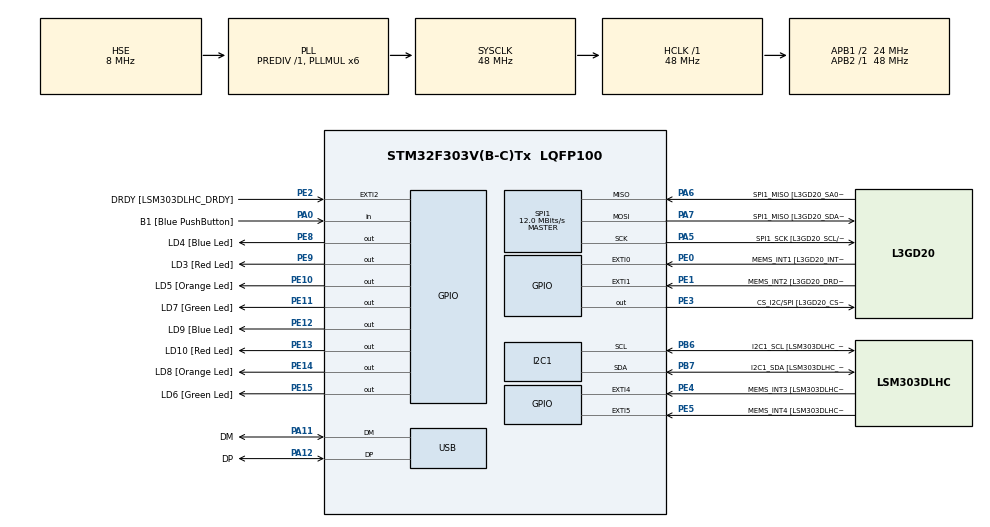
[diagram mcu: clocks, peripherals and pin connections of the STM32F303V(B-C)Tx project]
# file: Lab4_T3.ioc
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I2C1.Timing=0x00201D2B
I2C1.Timing-I2C=0x2000090E
Mcu.Family=STM32F3
Mcu.Name=STM32F303V(B-C)Tx
Mcu.Package=LQFP100
NVIC.PriorityGroup=NVIC_PRIORITYGROUP_0
NVIC.TIM2_IRQn=true\:0\:0\:false\:false\:true\:true\:true\:true
PA0.GPIO_Label=B1 [Blue PushButton]
PA0.Signal=GPIO_Input
PA11.GPIO_Label=DM
PA11.Mode=Device
PA11.Signal=USB_DM
PA12.GPIO_Label=DP
PA12.Mode=Device
PA12.Signal=USB_DP
PA13.GPIO_Label=SWDIO
PA13.Mode=Serial_Wire
PA13.Signal=SYS_JTMS-SWDIO
PA14.GPIO_Label=SWCLK
PA14.Mode=Serial_Wire
PA14.Signal=SYS_JTCK-SWCLK
PA5.GPIO_Label=SPI1_SCK [L3GD20_SCL/SPC]
PA5.Mode=Full_Duplex_Master
PA5.Signal=SPI1_SCK
PA6.GPIO_Label=SPI1_MISO [L3GD20_SA0/SDO]
PA6.Mode=Full_Duplex_Master
PA6.Signal=SPI1_MISO
PA7.GPIO_Label=SPI1_MISO [L3GD20_SDA/SDI/SDO]
PA7.Mode=Full_Duplex_Master
PA7.Signal=SPI1_MOSI
PB3.GPIO_Label=SWO
PB3.Signal=SYS_JTDO-TRACESWO
PB6.GPIO_Label=I2C1_SCL [LSM303DLHC_SCL]
PB6.GPIO_Pu=GPIO_PULLUP
PB6.Mode=I2C
PB6.Signal=I2C1_SCL
PB7.GPIO_Label=I2C1_SDA [LSM303DLHC_SDA]
PB7.GPIO_Pu=GPIO_PULLUP
PB7.Mode=I2C
PB7.Signal=I2C1_SDA
PC14-OSC32_IN.GPIO_Label=OSC32_IN
PC14-OSC32_IN.Signal=RCC_OSC32_IN
PC15-OSC32_OUT.GPIO_Label=OSC32_OUT
PC15-OSC32_OUT.Signal=RCC_OSC32_OUT
PE0.GPIO_Label=MEMS_INT1 [L3GD20_INT1]
PE0.GPIO_ModeDefaultEXTI=GPIO_MODE_EVT_RISING
PE0.Signal=GPXTI0
PE1.GPIO_Label=MEMS_INT2 [L3GD20_DRDY/INT2]
PE1.GPIO_ModeDefaultEXTI=GPIO_MODE_EVT_RISING
PE1.Signal=GPXTI1
PE10.GPIO_Label=LD5 [Orange Led]
PE10.Signal=GPIO_Output
PE11.GPIO_Label=LD7 [Green Led]
PE11.Signal=GPIO_Output
PE12.GPIO_Label=LD9 [Blue Led]
PE12.Signal=GPIO_Output
PE13.GPIO_Label=LD10 [Red Led]
PE13.Signal=GPIO_Output
PE14.GPIO_Label=LD8 [Orange Led]
PE14.Signal=GPIO_Output
PE15.GPIO_Label=LD6 [Green Led]
PE15.Signal=GPIO_Output
PE2.GPIO_Label=DRDY [LSM303DLHC_DRDY]
PE2.GPIO_ModeDefaultEXTI=GPIO_MODE_EVT_RISING
PE2.Signal=GPXTI2
PE3.GPIO_Label=CS_I2C/SPI [L3GD20_CS_I2C/SPI]
PE3.Signal=GPIO_Output
PE4.GPIO_Label=MEMS_INT3 [LSM303DLHC_INT1]
PE4.GPIO_ModeDefaultEXTI=GPIO_MODE_EVT_RISING
PE4.Signal=GPXTI4
PE5.GPIO_Label=MEMS_INT4 [LSM303DLHC_INT2]
PE5.GPIO_ModeDefaultEXTI=GPIO_MODE_EVT_RISING
PE5.Signal=GPXTI5
PE8.GPIO_Label=LD4 [Blue Led]
PE8.Signal=GPIO_Output
PE9.GPIO_Label=LD3 [Red Led]
PE9.Signal=GPIO_Output
PF0-OSC_IN.GPIO_Label=OSC_IN
PF0-OSC_IN.Mode=HSE-External-Clock-Source
PF0-OSC_IN.Signal=RCC_OSC_IN
PF1-OSC_OUT.GPIO_Label=OSC_OUT
PF1-OSC_OUT.Signal=RCC_OSC_OUT
ProjectManager.HeapSize=0x200
ProjectManager.StackSize=0x400
ProjectManager.TargetToolchain=CMake
RCC.AHBFreq_Value=48000000
RCC.APB1CLKDivider=RCC_HCLK_DIV2
RCC.APB1Freq_Value=24000000
RCC.APB1TimFreq_Value=48000000
RCC.APB2Freq_Value=48000000
RCC.APB2TimFreq_Value=48000000
RCC.CortexFreq_Value=48000000
RCC.HCLKFreq_Value=48000000
RCC.HSE_VALUE=8000000
RCC.HSI_VALUE=8000000
RCC.LSE_VALUE=32768
RCC.PLLMUL=RCC_PLL_MUL6
RCC.SYSCLKFreq_VALUE=48000000
RCC.SYSCLKSourceVirtual=RCC_SYSCLKSOURCE_PLLCLK
RCC.USBFreq_Value=48000000
SPI1.BaudRatePrescaler=SPI_BAUDRATEPRESCALER_4
SPI1.BaudRatePrescaler-Full_Duplex_Master=SPI_BAUDRATEPRESCALER_2
SPI1.CalculateBaudRate=12.0 MBits/s
SPI1.CalculateBaudRate-Full_Duplex_Master=24.0 MBits/s
SPI1.Direction=SPI_DIRECTION_2LINES
SPI1.Mode=SPI_MODE_MASTER
SPI1.Mode-Full_Duplex_Master=SPI_MODE_MASTER
SPI1.VirtualType=VM_MASTER
TIM2.Prescaler=47999
VP_TIM2_VS_ClockSourceINT.Mode=Internal
board=STM32F3DISCOVERY

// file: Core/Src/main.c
/**
  ******************************************************************************
  * @file           : main.c
  * @brief          : Lab 4 Task 3 - Blink 3 LEDs at Different Rates Using Timer Interrupt
  * @description    : This program uses TIM2 to generate a 1ms interrupt and software counters
  *                   to blink 3 LEDs at different frequencies:
  *                   - LED1: 500 ms (1 Hz)
  *                   - LED2: 200 ms (5 Hz)
  *                   - LED3: 100 ms (10 Hz)
  ******************************************************************************
  * Copyright (c) 2026 STMicroelectronics.
  * All rights reserved.
  ******************************************************************************
  */

#include "main.h"
#include <stdint.h>

/* Structure to hold LED configuration */
typedef struct {
  GPIO_TypeDef* port;
  uint16_t pin;
  uint16_t threshold_ms;
  uint16_t counter;
  uint8_t state;
} LED_Config_t;

#define LED1_THRESHOLD    500   /* 500 ms for 1 Hz blink */
#define LED2_THRESHOLD    200   /* 200 ms for 5 Hz blink */
#define LED3_THRESHOLD    100   /* 100 ms for 10 Hz blink */

I2C_HandleTypeDef hi2c1;
SPI_HandleTypeDef hspi1;
TIM_HandleTypeDef htim2;
PCD_HandleTypeDef hpcd_USB_FS;

/* LED configuration array */
LED_Config_t leds[3];

/* Timer interrupt counter (increments every 1ms) */
static volatile uint32_t timer_ms = 0;

void SystemClock_Config(void);
static void MX_GPIO_Init(void);
static void MX_I2C1_Init(void);
static void MX_SPI1_Init(void);
static void MX_TIM2_Init(void);
static void MX_USB_PCD_Init(void);

/* LED control functions */
static void LED_Init(void);
static void LED_Toggle(LED_Config_t* led);

/**
  * @brief Initialize LED configurations
  * @param None
  * @retval None
  */
static void LED_Init(void)
{
  /* Initialize LED1 (GPIOE, Pin 8) - using onboard LED3 */
  leds[0].port = GPIOE;
  leds[0].pin = GPIO_PIN_8;
  leds[0].threshold_ms = LED1_THRESHOLD;
  leds[0].counter = 0;
  leds[0].state = 0;

  /* Initialize LED2 (GPIOE, Pin 9) - using onboard LED4 */
  leds[1].port = GPIOE;
  leds[1].pin = GPIO_PIN_9;
  leds[1].threshold_ms = LED2_THRESHOLD;
  leds[1].counter = 0;
  leds[1].state = 0;

  /* Initialize LED3 (GPIOE, Pin 10) - using onboard LED5 */
  leds[2].port = GPIOE;
  leds[2].pin = GPIO_PIN_10;
  leds[2].threshold_ms = LED3_THRESHOLD;
  leds[2].counter = 0;
  leds[2].state = 0;

  /* Set all LEDs to OFF initially */
  HAL_GPIO_WritePin(GPIOE, GPIO_PIN_8 | GPIO_PIN_9 | GPIO_PIN_10, GPIO_PIN_RESET);
}

/**
  * @brief Toggle LED and reset counter
  * @param led: Pointer to LED configuration
  * @retval None
  */
static void LED_Toggle(LED_Config_t* led)
{
  if (led->state == 0)
  {
    /* Turn LED ON */
    HAL_GPIO_WritePin(led->port, led->pin, GPIO_PIN_SET);
    led->state = 1;
  }
  else
  {
    /* Turn LED OFF */
    HAL_GPIO_WritePin(led->port, led->pin, GPIO_PIN_RESET);
    led->state = 0;
  }
  /* Reset counter for next cycle */
  led->counter = 0;
}

int main(void)
{
  /* MCU Configuration -------------------------------------------------------*/

  /* Reset of all peripherals, Initializes the Flash interface and the Systick */
  HAL_Init();

  /* Configure the system clock */
  SystemClock_Config();

  /* Initialize all configured peripherals */
  MX_GPIO_Init();
  MX_I2C1_Init();
  MX_SPI1_Init();
  MX_TIM2_Init();
  MX_USB_PCD_Init();

  /* USER CODE BEGIN 2 */

  /* Initialize LED configuration structures */
  LED_Init();

  /* Start TIM2 in interrupt mode (generates 1ms interrupt) */
  if (HAL_TIM_Base_Start_IT(&htim2) != HAL_OK)
  {
    Error_Handler();
  }

  /* USER CODE END 2 */

  /* Infinite loop */
  while (1)
  {

    /* USER CODE BEGIN 3 */
    /* Main loop is now free for other tasks while LED blinking
       happens in the timer interrupt handler */
    HAL_Delay(10);  /* Small delay to prevent watchdog timeout */
  }
  /* USER CODE END 3 */
}

/**
  * @brief Timer Interrupt Callback - Called every 1ms when TIM2 overflows
  * @param htim: pointer to a TIM_HandleTypeDef structure that contains
  *              the configuration information for the specified TIM.
  * @retval None
  * @note This function is called from interrupt context, keep it as fast as possible
  */
void HAL_TIM_PeriodElapsedCallback(TIM_HandleTypeDef *htim)
{
  if (htim->Instance == TIM2)
  {
    /* Increment global millisecond counter */
    timer_ms++;

    /* Process each LED's counter and toggle if threshold reached */
    for (int i = 0; i < 3; i++)
    {
      leds[i].counter++;

      /* Check if LED counter has reached its threshold */
      if (leds[i].counter >= leds[i].threshold_ms)
      {
        /* Toggle the LED and reset its counter */
        LED_Toggle(&leds[i]);
      }
    }
  }
}

void SystemClock_Config(void)
{
  RCC_OscInitTypeDef RCC_OscInitStruct = {0};
  RCC_ClkInitTypeDef RCC_ClkInitStruct = {0};
  RCC_PeriphCLKInitTypeDef PeriphClkInit = {0};

  /** Initializes the RCC Oscillators according to the specified parameters
  * in the RCC_OscInitTypeDef structure.
  */
  RCC_OscInitStruct.OscillatorType = RCC_OSCILLATORTYPE_HSI|RCC_OSCILLATORTYPE_HSE;
  RCC_OscInitStruct.HSEState = RCC_HSE_BYPASS;
  RCC_OscInitStruct.HSEPredivValue = RCC_HSE_PREDIV_DIV1;
  RCC_OscInitStruct.HSIState = RCC_HSI_ON;
  RCC_OscInitStruct.HSICalibrationValue = RCC_HSICALIBRATION_DEFAULT;
  RCC_OscInitStruct.PLL.PLLState = RCC_PLL_ON;
  RCC_OscInitStruct.PLL.PLLSource = RCC_PLLSOURCE_HSE;
  RCC_OscInitStruct.PLL.PLLMUL = RCC_PLL_MUL6;
  if (HAL_RCC_OscConfig(&RCC_OscInitStruct) != HAL_OK)
  {
    Error_Handler();
  }

  /** Initializes the CPU, AHB and APB buses clocks
  */
  RCC_ClkInitStruct.ClockType = RCC_CLOCKTYPE_HCLK|RCC_CLOCKTYPE_SYSCLK
                              |RCC_CLOCKTYPE_PCLK1|RCC_CLOCKTYPE_PCLK2;
  RCC_ClkInitStruct.SYSCLKSource = RCC_SYSCLKSOURCE_PLLCLK;
  RCC_ClkInitStruct.AHBCLKDivider = RCC_SYSCLK_DIV1;
  RCC_ClkInitStruct.APB1CLKDivider = RCC_HCLK_DIV2;
  RCC_ClkInitStruct.APB2CLKDivider = RCC_HCLK_DIV1;

  if (HAL_RCC_ClockConfig(&RCC_ClkInitStruct, FLASH_LATENCY_1) != HAL_OK)
  {
    Error_Handler();
  }
  PeriphClkInit.PeriphClockSelection = RCC_PERIPHCLK_USB|RCC_PERIPHCLK_I2C1;
  PeriphClkInit.I2c1ClockSelection = RCC_I2C1CLKSOURCE_HSI;
  PeriphClkInit.USBClockSelection = RCC_USBCLKSOURCE_PLL;
  if (HAL_RCCEx_PeriphCLKConfig(&PeriphClkInit) != HAL_OK)
  {
    Error_Handler();
  }
}

static void MX_I2C1_Init(void)
{

  hi2c1.Instance = I2C1;
  hi2c1.Init.Timing = 0x2000090E;
  hi2c1.Init.OwnAddress1 = 0;
  hi2c1.Init.AddressingMode = I2C_ADDRESSINGMODE_7BIT;
  hi2c1.Init.DualAddressMode = I2C_DUALADDRESS_DISABLE;
  hi2c1.Init.OwnAddress2 = 0;
  hi2c1.Init.OwnAddress2Masks = I2C_OA2_NOMASK;
  hi2c1.Init.GeneralCallMode = I2C_GENERALCALL_DISABLE;
  hi2c1.Init.NoStretchMode = I2C_NOSTRETCH_DISABLE;
  if (HAL_I2C_Init(&hi2c1) != HAL_OK)
  {
    Error_Handler();
  }

  /** Configure Analogue filter
  */
  if (HAL_I2CEx_ConfigAnalogFilter(&hi2c1, I2C_ANALOGFILTER_ENABLE) != HAL_OK)
  {
    Error_Handler();
  }

  /** Configure Digital filter
  */
  if (HAL_I2CEx_ConfigDigitalFilter(&hi2c1, 0) != HAL_OK)
  {
    Error_Handler();
  }

}

static void MX_SPI1_Init(void)
{

  /* SPI1 parameter configuration*/
  hspi1.Instance = SPI1;
  hspi1.Init.Mode = SPI_MODE_MASTER;
  hspi1.Init.Direction = SPI_DIRECTION_2LINES;
  hspi1.Init.DataSize = SPI_DATASIZE_4BIT;
  hspi1.Init.CLKPolarity = SPI_POLARITY_LOW;
  hspi1.Init.CLKPhase = SPI_PHASE_1EDGE;
  hspi1.Init.NSS = SPI_NSS_SOFT;
  hspi1.Init.BaudRatePrescaler = SPI_BAUDRATEPRESCALER_4;
  hspi1.Init.FirstBit = SPI_FIRSTBIT_MSB;
  hspi1.Init.TIMode = SPI_TIMODE_DISABLE;
  hspi1.Init.CRCCalculation = SPI_CRCCALCULATION_DISABLE;
  hspi1.Init.CRCPolynomial = 7;
  hspi1.Init.CRCLength = SPI_CRC_LENGTH_DATASIZE;
  hspi1.Init.NSSPMode = SPI_NSS_PULSE_ENABLE;
  if (HAL_SPI_Init(&hspi1) != HAL_OK)
  {
    Error_Handler();
  }

}

static void MX_TIM2_Init(void)
{

  TIM_ClockConfigTypeDef sClockSourceConfig = {0};
  TIM_MasterConfigTypeDef sMasterConfig = {0};

  htim2.Instance = TIM2;
  /* EXACT 1ms CONFIGURATION */
  htim2.Init.Prescaler = 71;        /* 72MHz / 72 = 1MHz */
  htim2.Init.CounterMode = TIM_COUNTERMODE_UP;
  htim2.Init.Period = 999;          /* 1MHz / 1000 = 1kHz = 1ms */
  htim2.Init.ClockDivision = TIM_CLOCKDIVISION_DIV1;
  htim2.Init.AutoReloadPreload = TIM_AUTORELOAD_PRELOAD_DISABLE;
  if (HAL_TIM_Base_Init(&htim2) != HAL_OK)
  {
    Error_Handler();
  }
  sClockSourceConfig.ClockSource = TIM_CLOCKSOURCE_INTERNAL;
  if (HAL_TIM_ConfigClockSource(&htim2, &sClockSourceConfig) != HAL_OK)
  {
    Error_Handler();
  }
  sMasterConfig.MasterOutputTrigger = TIM_TRGO_RESET;
  sMasterConfig.MasterSlaveMode = TIM_MASTERSLAVEMODE_DISABLE;
  if (HAL_TIMEx_MasterConfigSynchronization(&htim2, &sMasterConfig) != HAL_OK)
  {
    Error_Handler();
  }

}

static void MX_USB_PCD_Init(void)
{

  hpcd_USB_FS.Instance = USB;
  hpcd_USB_FS.Init.dev_endpoints = 8;
  hpcd_USB_FS.Init.speed = PCD_SPEED_FULL;
  hpcd_USB_FS.Init.phy_itface = PCD_PHY_EMBEDDED;
  hpcd_USB_FS.Init.low_power_enable = DISABLE;
  hpcd_USB_FS.Init.battery_charging_enable = DISABLE;
  if (HAL_PCD_Init(&hpcd_USB_FS) != HAL_OK)
  {
    Error_Handler();
  }

}

static void MX_GPIO_Init(void)
{
  GPIO_InitTypeDef GPIO_InitStruct = {0};

  /* GPIO Ports Clock Enable */
  __HAL_RCC_GPIOE_CLK_ENABLE();
  __HAL_RCC_GPIOC_CLK_ENABLE();
  __HAL_RCC_GPIOF_CLK_ENABLE();
  __HAL_RCC_GPIOA_CLK_ENABLE();
  __HAL_RCC_GPIOB_CLK_ENABLE();

  /*Configure GPIO pin Output Level */
  HAL_GPIO_WritePin(GPIOE, GPIO_PIN_8|GPIO_PIN_9|GPIO_PIN_10, GPIO_PIN_RESET);

  /*Configure GPIO pins : PE8, PE9, PE10 as outputs for LEDs */
  GPIO_InitStruct.Pin = GPIO_PIN_8|GPIO_PIN_9|GPIO_PIN_10;
  GPIO_InitStruct.Mode = GPIO_MODE_OUTPUT_PP;
  GPIO_InitStruct.Pull = GPIO_NOPULL;
  GPIO_InitStruct.Speed = GPIO_SPEED_FREQ_LOW;
  HAL_GPIO_Init(GPIOE, &GPIO_InitStruct);

  /*Configure GPIO pin : B1_Pin */
  GPIO_InitStruct.Pin = GPIO_PIN_0;
  GPIO_InitStruct.Mode = GPIO_MODE_INPUT;
  GPIO_InitStruct.Pull = GPIO_NOPULL;
  HAL_GPIO_Init(GPIOA, &GPIO_InitStruct);

}

void Error_Handler(void)
{
  __disable_irq();
  while (1)
  {
  }
}
